AUTOSAR XML (schema 4.0)
standard types defined: float32, float64, sint16, sint32, sint8, uint16, uint32, uint8, void, boolean
package /ImplDataTypes
  impl type Impl_MultiStateBtnType: implementation-data-type=uint8, type-emitter=RTE
package /MappingSets
  data type mapping set MappingSet
package /PortInterfaces/SenderReceiver
  sender receiver interface SrIf_SeatCtrlBtns
    data DE_HeightBtnState: type=Impl_MultiStateBtnType
    data DE_InclineBtnState: type=Impl_MultiStateBtnType
    data DE_SlideBtnState: type=Impl_MultiStateBtnType
  sender receiver interface SrIf_SeatCtrlData
    data DE_Height: type=uint8
    data DE_Incline: type=uint8
    data DE_Slide: type=uint8
package /SoftwareComponents
  swc implementation Impl_SWC_HMI: programming-language=C, sw-version=1.0.0, vendor-id=255, behavior=Ibhv_SWC_HMI
    code-descriptors:
      code Code: artifact-descriptors=autosar-engineering-object={short-label=SWC.c, category=SWSRC}
    resource consumption ResourceConsumption
  swc implementation Impl_SWC_Seat_Manger: programming-language=C, sw-version=1.0.0, vendor-id=255, behavior=Ibhv_SWC_Seat_Manger
    code-descriptors:
      code Code: artifact-descriptors=autosar-engineering-object={short-label=SWC.c, category=SWSRC}
    resource consumption ResourceConsumption
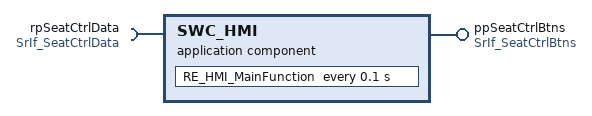
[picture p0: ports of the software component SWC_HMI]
  application sw component type SWC_HMI
    provide port ppSeatCtrlBtns: provided-interface=SrIf_SeatCtrlBtns
    require port rpSeatCtrlData: required-interface=SrIf_SeatCtrlData
    behavior Ibhv_SWC_HMI: data-type-mapping=MappingSet, handle-termination-and-restart=NO-SUPPORT
      timing event TE_RE_HMI_MainFunction_100ms: start-on-event=RE_HMI_MainFunction, period=0.1
      runnable RE_HMI_MainFunction
        data-receive-point-by-arguments:
          access DRP_rpSeatCtrlData_DE_Height: accessed-variable=rpSeatCtrlData.DE_Height
          access DRP_rpSeatCtrlData_DE_Incline: accessed-variable=rpSeatCtrlData.DE_Incline
          access DRP_rpSeatCtrlData_DE_Slide: accessed-variable=rpSeatCtrlData.DE_Slide
        data-send-points:
          access DSP_ppSeatCtrlBtns_DE_HeightBtnState: accessed-variable=ppSeatCtrlBtns.DE_HeightBtnState
          access DSP_ppSeatCtrlBtns_DE_InclineBtnState: accessed-variable=ppSeatCtrlBtns.DE_InclineBtnState
          access DSP_ppSeatCtrlBtns_DE_SlideBtnState: accessed-variable=ppSeatCtrlBtns.DE_SlideBtnState
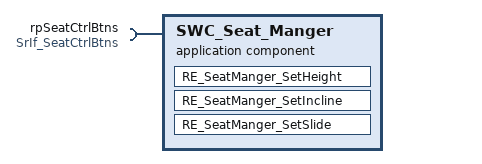
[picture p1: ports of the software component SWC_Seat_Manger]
  application sw component type SWC_Seat_Manger
    require port rpSeatCtrlBtns: required-interface=SrIf_SeatCtrlBtns
    behavior Ibhv_SWC_Seat_Manger: data-type-mapping=MappingSet, handle-termination-and-restart=NO-SUPPORT
      data received event DRE_rpSeatCtrlBtns_DE_HeightBtnState: start-on-event=RE_SeatManger_SetHeight, data=rpSeatCtrlBtns.DE_HeightBtnState
      data received event DRE_rpSeatCtrlBtns_DE_InclineBtnState: start-on-event=RE_SeatManger_SetIncline, data=rpSeatCtrlBtns.DE_InclineBtnState
      data received event DRE_rpSeatCtrlBtns_DE_SlideBtnState: start-on-event=RE_SeatManger_SetSlide, data=rpSeatCtrlBtns.DE_SlideBtnState
      runnable RE_SeatManger_SetHeight
        data-receive-point-by-arguments:
          access DRP_rpSeatCtrlBtns_DE_HeightBtnState: accessed-variable=rpSeatCtrlBtns.DE_HeightBtnState
      runnable RE_SeatManger_SetIncline
        data-receive-point-by-arguments:
          access DRP_rpSeatCtrlBtns_DE_InclineBtnState: accessed-variable=rpSeatCtrlBtns.DE_InclineBtnState
      runnable RE_SeatManger_SetSlide
        data-receive-point-by-arguments:
          access DRP_rpSeatCtrlBtns_DE_SlideBtnState: accessed-variable=rpSeatCtrlBtns.DE_SlideBtnState
package /Compositions
  composition sw component type SeatAdjManger_task2_AutoSAR_SprintsComposition
    component SWC_HMI: type=SWC_HMI
    component SWC_Seat_Manger: type=SWC_Seat_Manger
    connect SWC_HMI.ppSeatCtrlBtns -> SWC_Seat_Manger.rpSeatCtrlBtns
